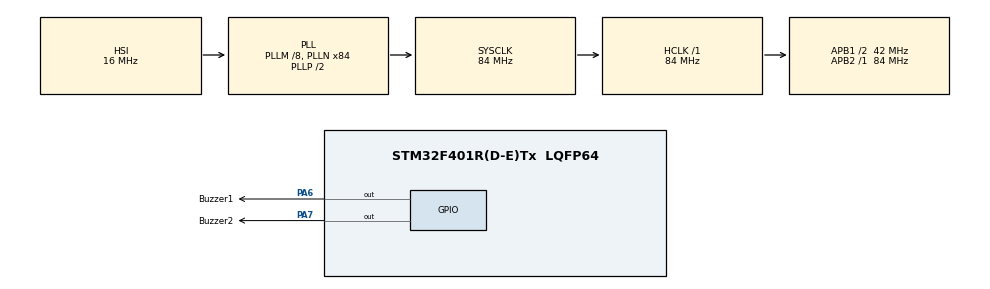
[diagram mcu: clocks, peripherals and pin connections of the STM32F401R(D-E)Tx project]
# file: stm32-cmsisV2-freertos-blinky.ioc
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FREERTOS.Tasks01=buzz01,24,128,StartBuzzer01,Default,NULL,Dynamic,NULL,NULL;buzz02,16,128,StartBuzzer02,Default,NULL,Dynamic,NULL,NULL
Mcu.Family=STM32F4
Mcu.Name=STM32F401R(D-E)Tx
Mcu.Package=LQFP64
NVIC.PriorityGroup=NVIC_PRIORITYGROUP_4
NVIC.TIM1_UP_TIM10_IRQn=true\:15\:0\:false\:false\:true\:false\:false\:true
NVIC.TimeBase=TIM1_UP_TIM10_IRQn
NVIC.TimeBaseIP=TIM1
PA6.GPIO_Label=Buzzer1
PA6.Signal=GPIO_Output
PA7.GPIO_Label=Buzzer2
PA7.Signal=GPIO_Output
ProjectManager.HeapSize=0x200
ProjectManager.StackSize=0x400
ProjectManager.TargetToolchain=STM32CubeIDE
RCC.48MHZClocksFreq_Value=42000000
RCC.AHBFreq_Value=84000000
RCC.APB1CLKDivider=RCC_HCLK_DIV2
RCC.APB1Freq_Value=42000000
RCC.APB1TimFreq_Value=84000000
RCC.APB2Freq_Value=84000000
RCC.APB2TimFreq_Value=84000000
RCC.CortexFreq_Value=84000000
RCC.HCLKFreq_Value=84000000
RCC.HSE_VALUE=25000000
RCC.HSI_VALUE=16000000
RCC.LSE_VALUE=32768
RCC.PLLM=8
RCC.PLLN=84
RCC.SYSCLKFreq_VALUE=84000000
RCC.SYSCLKSource=RCC_SYSCLKSOURCE_PLLCLK
RCC.VCOOutputFreq_Value=168000000
VP_FREERTOS_VS_CMSIS_V2.Mode=CMSIS_V2
VP_SYS_VS_tim1.Mode=TIM1
board=custom

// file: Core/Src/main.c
/* USER CODE BEGIN Header */
/**
 ******************************************************************************
 * @file           : main.c
 * @brief          : Main program body
 ******************************************************************************
 * @attention
 *
 * Copyright (c) 2022 STMicroelectronics.
 * All rights reserved.
 *
 * This software is licensed under terms that can be found in the LICENSE file
 * in the root directory of this software component.
 * If no LICENSE file comes with this software, it is provided AS-IS.
 *
 ******************************************************************************
 */
/* USER CODE END Header */
#include "main.h"
#include "cmsis_os.h"

/* Definitions for buzz01 */
osThreadId_t buzz01Handle;
const osThreadAttr_t buzz01_attributes = {
  .name = "buzz01",
  .stack_size = 128 * 4,
  .priority = (osPriority_t) osPriorityNormal,
};
/* Definitions for buzz02 */
osThreadId_t buzz02Handle;
const osThreadAttr_t buzz02_attributes = {
  .name = "buzz02",
  .stack_size = 128 * 4,
  .priority = (osPriority_t) osPriorityBelowNormal,
};

void SystemClock_Config(void);
static void MX_GPIO_Init(void);
void StartBuzzer01(void *argument);
void StartBuzzer02(void *argument);

int main(void)
{

  /* MCU Configuration--------------------------------------------------------*/

  /* Reset of all peripherals, Initializes the Flash interface and the Systick. */
  HAL_Init();

  /* Configure the system clock */
  SystemClock_Config();

  /* Initialize all configured peripherals */
  MX_GPIO_Init();

  /* Init scheduler */
  osKernelInitialize();

  /* Create the thread(s) */
  /* creation of buzz01 */
  buzz01Handle = osThreadNew(StartBuzzer01, NULL, &buzz01_attributes);

  /* creation of buzz02 */
  buzz02Handle = osThreadNew(StartBuzzer02, NULL, &buzz02_attributes);

  /* Start scheduler */
  osKernelStart();

  /* We should never get here as control is now taken by the scheduler */
  /* Infinite loop */
  while (1)
  {

  }
}

void SystemClock_Config(void)
{
  RCC_OscInitTypeDef RCC_OscInitStruct = {0};
  RCC_ClkInitTypeDef RCC_ClkInitStruct = {0};

  /** Configure the main internal regulator output voltage
  */
  __HAL_RCC_PWR_CLK_ENABLE();
  __HAL_PWR_VOLTAGESCALING_CONFIG(PWR_REGULATOR_VOLTAGE_SCALE2);
  /** Initializes the RCC Oscillators according to the specified parameters
  * in the RCC_OscInitTypeDef structure.
  */
  RCC_OscInitStruct.OscillatorType = RCC_OSCILLATORTYPE_HSI;
  RCC_OscInitStruct.HSIState = RCC_HSI_ON;
  RCC_OscInitStruct.HSICalibrationValue = RCC_HSICALIBRATION_DEFAULT;
  RCC_OscInitStruct.PLL.PLLState = RCC_PLL_ON;
  RCC_OscInitStruct.PLL.PLLSource = RCC_PLLSOURCE_HSI;
  RCC_OscInitStruct.PLL.PLLM = 8;
  RCC_OscInitStruct.PLL.PLLN = 84;
  RCC_OscInitStruct.PLL.PLLP = RCC_PLLP_DIV2;
  RCC_OscInitStruct.PLL.PLLQ = 4;
  if (HAL_RCC_OscConfig(&RCC_OscInitStruct) != HAL_OK)
  {
    Error_Handler();
  }
  /** Initializes the CPU, AHB and APB buses clocks
  */
  RCC_ClkInitStruct.ClockType = RCC_CLOCKTYPE_HCLK|RCC_CLOCKTYPE_SYSCLK
                              |RCC_CLOCKTYPE_PCLK1|RCC_CLOCKTYPE_PCLK2;
  RCC_ClkInitStruct.SYSCLKSource = RCC_SYSCLKSOURCE_PLLCLK;
  RCC_ClkInitStruct.AHBCLKDivider = RCC_SYSCLK_DIV1;
  RCC_ClkInitStruct.APB1CLKDivider = RCC_HCLK_DIV2;
  RCC_ClkInitStruct.APB2CLKDivider = RCC_HCLK_DIV1;

  if (HAL_RCC_ClockConfig(&RCC_ClkInitStruct, FLASH_LATENCY_2) != HAL_OK)
  {
    Error_Handler();
  }
}

static void MX_GPIO_Init(void)
{
  GPIO_InitTypeDef GPIO_InitStruct = {0};

  /* GPIO Ports Clock Enable */
  __HAL_RCC_GPIOA_CLK_ENABLE();

  /*Configure GPIO pin Output Level */
  HAL_GPIO_WritePin(GPIOA, Buzzer1_Pin|Buzzer2_Pin, GPIO_PIN_RESET);

  /*Configure GPIO pins : Buzzer1_Pin Buzzer2_Pin */
  GPIO_InitStruct.Pin = Buzzer1_Pin|Buzzer2_Pin;
  GPIO_InitStruct.Mode = GPIO_MODE_OUTPUT_PP;
  GPIO_InitStruct.Pull = GPIO_NOPULL;
  GPIO_InitStruct.Speed = GPIO_SPEED_FREQ_LOW;
  HAL_GPIO_Init(GPIOA, &GPIO_InitStruct);

}

void StartBuzzer01(void *argument)
{
  /* USER CODE BEGIN 5 */
  /* Infinite loop */
  for (;;)
  {
    HAL_GPIO_TogglePin(GPIOA, GPIO_PIN_6);
    osDelay(500);
  }
  /*Graceful Exit*/
  osThreadTerminate(NULL);
  /* USER CODE END 5 */
}

void StartBuzzer02(void *argument)
{
  /* USER CODE BEGIN StartBuzzer02 */
  /* Infinite loop */
  for (;;)
  {
    HAL_GPIO_TogglePin(GPIOA, GPIO_PIN_7);
    osDelay(300);
  }
  /*Graceful Exit*/
  osThreadTerminate(NULL);
  /* USER CODE END StartBuzzer02 */
}

void HAL_TIM_PeriodElapsedCallback(TIM_HandleTypeDef *htim)
{
  if (htim->Instance == TIM1) {
    HAL_IncTick();
  }
}

void Error_Handler(void)
{
  __disable_irq();
  while (1)
  {
  }
}
